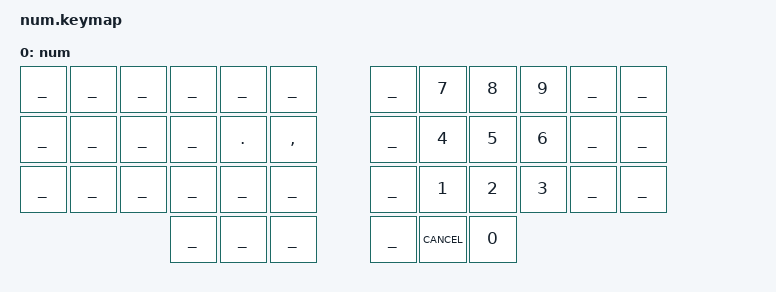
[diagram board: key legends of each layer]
ZMK_LAYER(num,    // 3
//╭─────────────┬─────────────┬─────────────┬─────────────┬─────────────┬─────────────╮ ╭─────────────┬─────────────┬─────────────┬─────────────┬─────────────┬─────────────╮
    ___           ___           ___           ___           ___           ___             ___           &kp N7        &kp N8        &kp N9        ___           ___
//├─────────────┼─────────────┼─────────────┼─────────────┼─────────────┼─────────────┤ ├─────────────┼─────────────┼─────────────┼─────────────┼─────────────┴─────────────┤
    ___           ___           ___           ___           &kp DOT       &kp COMMA       ___           &kp N4        &kp N5        &kp N6        ___           ___
//├─────────────┼─────────────┼─────────────┼─────────────┼─────────────┼─────────────┤ ├─────────────┼─────────────┼─────────────┼─────────────┼─────────────┴─────────────┤
    ___           ___           ___           ___           ___           ___             ___           &kp N1        &kp N2        &kp N3        ___           ___
//╰─────────────┴─────────────┴─────────────┼─────────────┼─────────────┼─────────────┤ ├─────────────┼─────────────┼─────────────┼─────────────┴─────────────┴─────────────╯
                                              ___           ___           ___             ___           CANCEL        &kp N0
//                                          ╰─────────────┴─────────────┴─────────────╯ ╰─────────────┴─────────────┴─────────────╯
)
